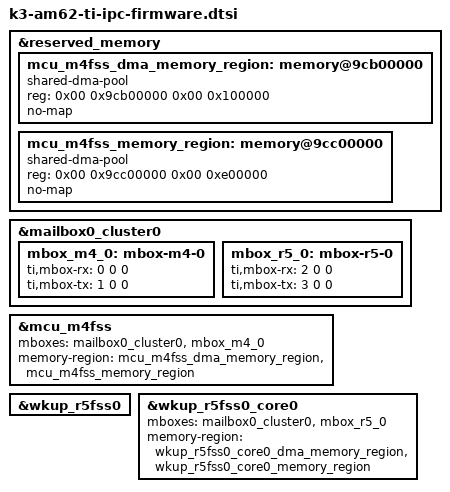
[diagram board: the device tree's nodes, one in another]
// SPDX-License-Identifier: GPL-2.0-only OR MIT
/**
 * Device Tree Source for enabling IPC using TI SDK firmware on AM62 SoCs
 *
 * Copyright (C) 2021-2025 Texas Instruments Incorporated - https://www.ti.com/
 */

&reserved_memory {
	mcu_m4fss_dma_memory_region: memory@9cb00000 {
		compatible = "shared-dma-pool";
		reg = <0x00 0x9cb00000 0x00 0x100000>;
		no-map;
	};

	mcu_m4fss_memory_region: memory@9cc00000 {
		compatible = "shared-dma-pool";
		reg = <0x00 0x9cc00000 0x00 0xe00000>;
		no-map;
	};
};

&mailbox0_cluster0 {
	status = "okay";

	mbox_m4_0: mbox-m4-0 {
		ti,mbox-rx = <0 0 0>;
		ti,mbox-tx = <1 0 0>;
	};

	mbox_r5_0: mbox-r5-0 {
		ti,mbox-rx = <2 0 0>;
		ti,mbox-tx = <3 0 0>;
	};
};

&mcu_m4fss {
	mboxes = <&mailbox0_cluster0 &mbox_m4_0>;
	memory-region = <&mcu_m4fss_dma_memory_region>,
			<&mcu_m4fss_memory_region>;
	status = "okay";
};

&wkup_r5fss0 {
	status = "okay";
};

&wkup_r5fss0_core0 {
	mboxes = <&mailbox0_cluster0 &mbox_r5_0>;
	memory-region = <&wkup_r5fss0_core0_dma_memory_region>,
			<&wkup_r5fss0_core0_memory_region>;
	status = "okay";
};
